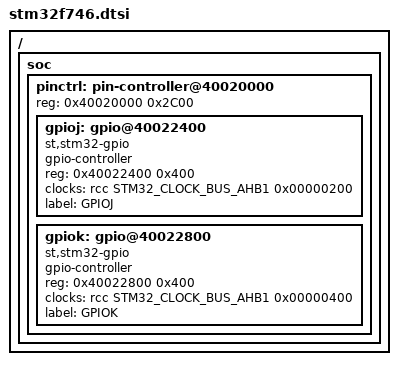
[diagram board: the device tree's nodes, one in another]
/*
 * Copyright (c) 2018 Yurii Hamann
 *
 * SPDX-License-Identifier: Apache-2.0
 */

#include <st/stm32f7.dtsi>

/ {
	soc {
		pinctrl: pin-controller@40020000 {
			reg = <0x40020000 0x2C00>;

			gpioj: gpio@40022400 {
				compatible = "st,stm32-gpio";
				gpio-controller;
				#gpio-cells = <2>;
				reg = <0x40022400 0x400>;
				clocks = <&rcc STM32_CLOCK_BUS_AHB1 0x00000200>;
				label = "GPIOJ";
			};

			gpiok: gpio@40022800 {
				compatible = "st,stm32-gpio";
				gpio-controller;
				#gpio-cells = <2>;
				reg = <0x40022800 0x400>;
				clocks = <&rcc STM32_CLOCK_BUS_AHB1 0x00000400>;
				label = "GPIOK";
			};
		};
	};
};
